# ILF3_ICONT register map
Vendor: Texas Instruments
Peripheral module from a debugger description file (folder TDA2Px).
Registers are 32-bit, access per field, reset 0x0 unless marked. A register's access mark holds for its fields unless they carry their own. Offsets are as the file gives them; lines under a group give offsets from that group; [hi:lo] are bit positions; {n}, {i} and the like mark numbered series; 'fields as' and 'values as' point back to an identical list; <NAME> marks a mode.

## ILF3_ICONT
0x00 ILF3_REVISION ro reset not defined — IP revision identifier (X.Y.R) Used by software to track features, bugs, and compatibility
  [31:0] REVISION — IP revision
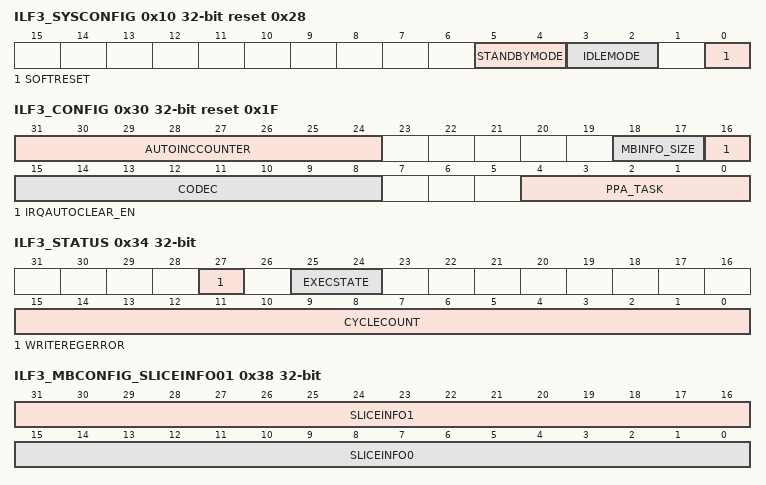
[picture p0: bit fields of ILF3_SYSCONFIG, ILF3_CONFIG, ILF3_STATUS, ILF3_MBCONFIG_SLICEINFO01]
0x10 ILF3_SYSCONFIG reset 0x28 — Clock management configuration
  [5:4] STANDBYMODE rw — Configuration of the local initiator state management mode. By definition, initiator may generate read/write transaction as long as it is out of STANDBY state.
    0=STANDBY_0 (Force-standby mode: Local initiator is unconditionally placed in STANDBY state. Backup mode, for debug only.); 1=STANDBY_1 (No-standby mode: Local initiator is unconditionally placed out of STANDBY state. Backup mode, for debug only.); 2=IP_2 (Smart-standby mode: Local initiator standby status depends on local conditions; that is, the module functional requirement from the initiator. IP module must not generate (initiator-related) wake-up events.); 3=IP_STANDBY_IP_3 (Smart-standby wakeup-capable mode: Local initiator standby status depends on local conditions; that is, the module functional requirement from the initiator. IP module may generate (master-related) wake-up events when in STANDBY state. Mode is relevant only if the appropriate IP module 'mwakeup' output is implemented.)
  [3:2] IDLEMODE rw — Configuration of the local target state management mode. By definition, target can handle read/write transaction as long as it is out of IDLE state.
    0=IDLE_IP_0 (Force-idle mode: Local target IDLE state follows (acknowledges) the system idle requests unconditionally; that is, regardless of the internal requirements of the IP module. Backup mode, for debug only.); 1=IDLE_1 (No-idle mode: Local target never enters IDLE state. Backup mode, for debug only.); 2=IDLE_IP_IP_(IRQ-_2 (Smart-idle mode: Local target IDLE state eventually follows (acknowledges) the system idle requests, depending on the internal requirements of the IP module. IP module must not generate (IRQ- or DMA-request-related) wake-up events.); 3=IDLE_IP_IP_(IRQ-_IDLE_IP_3 (Smart-idle wakeup-capable mode: Local target IDLE state eventually follows (acknowledges) the system idle requests, depending on the internal requirements of the IP module. IP module may generate (IRQ- or DMA-request-related) wake-up events when in IDLE state. Mode is relevant only if the appropriate IP module 'swakeup' output(s) is (are) implemented.)
  [0] SOFTRESET rw — Software reset (optional)
    0=Reset_done,_no_pending_action; 0=No_action; 1=Initiate_software_reset; 1=Reset_(software_or_other)_ongoing
0x18 ILF3_IRQ_EOI — End Of Interrupt number specification
  [0] LINE_NUMBER rw — Software End Of Interrupt (EOI) control. Write number of interrupt output.
    0=READ0 (EOI for interrupt output line #0); 0=EOI1 (Reads always 0 (no EOI memory)); 1=EOI1 (EOI for interrupt output line #1)
0x1C ILF3_IRQSTATUS_RAW_0 access not given — Per-event raw interrupt status vector, line 0. Raw status is set even if event is not enabled. Write 1 to set the (raw) status, mostly for debug.
  [0] EVENT0 — Settable raw status for event 0 (access RW W1toSet)
    0=No_action; 0=No_event_pending; 1=Event_pending; 1=Set_event_(debug)
0x20 ILF3_IRQSTATUS_0 access not given — Per-event 'enabled' interrupt status vector, line 0. Enabled status is not set unless event is enabled. Write 1 to clear the status after interrupt has been serviced (raw status gets cleared, that is, even if not enabled).
  [0] EVENT0 — Clearable, enabled status for event 0 (access RW W1toClr)
    0=No_action; 0=No_(enabled)_event_pending; 1=Event_pending; 1=Clear_(raw)_event
0x24 ILF3_IRQENABLE_SET_0 access not given — Per-event interrupt enable bit vector, line 0. Write 1 to set (enable interrupt). Readout equal to corresponding _CLR register.
  [0] ENABLE0 — Enable for event 0 (access RW W1toSet)
    0=No_action; 0=Interrupt_disabled_(masked); 1=Interrupt_enabled; 1=Enable_interrupt
0x28 ILF3_IRQENABLE_CLR_0 access not given — Per-event interrupt enable bit vector, line 0. Write 1 to clear (disable interrupt). Readout equal to corresponding _SET register.
  [0] ENABLE0 — Enable for event 0 (access RW W1toClr)
    0=No_action; 0=Interrupt_disabled_(masked); 1=Interrupt_enabled; 1=Disable_interrupt
0x30 ILF3_CONFIG reset 0x1F — Configuration register
  [31:24] AUTOINCCOUNTER rw — This field indicates the current increment in MB for the auto-increment mechanism. The value at reset is 0 and it is incremented at the end of each MB (or MBPair in MBAFF) process. When it reaches the MAX_COUNT value in MBCT (@0x78), it returns to 0.
  [18:17] MBINFO_SIZE rw — Selects one of the three different MBinfo sizes to be loaded.
    0=Use_Bi-16_MV_MB_info_size; 1=Use_16_MV_MB_info_size; 2=Use_Bi-4_MV_MB_info_size; 3=Forbiden_value_/_not_functional
  [16] IRQAUTOCLEAR_EN rw — 0x0: IRQ auto clear disabled, 0x1: IRQ auto clear enabled
  [15:8] CODEC rw — Indicates the codec to be used.
    0=H.264; 1=MPEG-1/-2; 2=MPEG-4; 3=VC-1; 4=AVS; 5=RV8; 6=RV9; 7=RV10; 8=On2_VP6; 9=On2_VP7; 10=H.263; 11=RCDO_(H.241); 15=GDP_filter
  [4:0] PPA_TASK rw — Bit 0: Load MB info Bit 1: Compute BS. Bit 2: Load MB. Bit 3: Filter MB. Bit 4: Store MB.
0x34 ILF3_STATUS ro — Provides information on the progress of the ILF3 execution.
  [27] WRITEREGERROR — This bit is cleared by a Start() command when in INITIALIZED or COMPLETED state.
    0=Normal_mode; 1=OCP_EXECUTING_1 (Attempting to write an internal register via an OCP write, while in EXECUTING state.)
  [25:24] EXECSTATE — Execution states.
    0=INITIALIZED; 1=HALTED; 2=EXECUTING; 3=COMPLETED
  [15:0] CYCLECOUNT — Total number of cycles executed
0x38 ILF3_MBCONFIG_SLICEINFO01 rw — MBConfig table contains pointers used by program to control the ILF3 units.
  [31:16] SLICEINFO1 — Parameter
  [15:0] SLICEINFO0 — Parameter
0x3C ILF3_MBCONFIG_SLICEINFO2 — MBConfig table contains pointers used by program to control the ILF3 units.
  [15:0] MBCONFIG_ADDRESS_SLICEINFO2 rw — Parameter
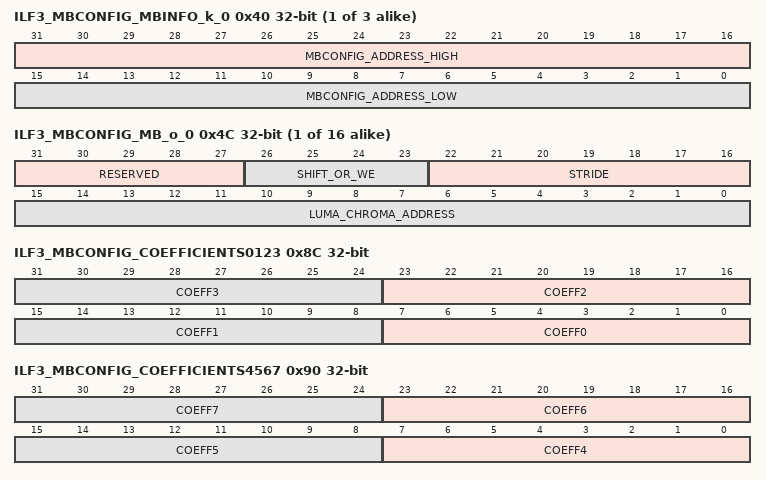
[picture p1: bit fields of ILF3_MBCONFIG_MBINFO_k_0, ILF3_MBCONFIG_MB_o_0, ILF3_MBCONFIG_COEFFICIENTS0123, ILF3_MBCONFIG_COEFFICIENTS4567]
{0x40+4i} ILF3_MBCONFIG_MBINFO_k_{i} rw (i=0..2) — MBConfig table contains pointers used by program to control the ILF3 units
  [31:16] MBCONFIG_ADDRESS_HIGH — Parameter
  [15:0] MBCONFIG_ADDRESS_LOW — Parameter
{0x4C+4i} ILF3_MBCONFIG_MB_o_{i} (i=0..15) — MBConfig table contains pointers used by program to control the ILF3 units
  [31:27] RESERVED ro — Read returns 0
  [26:23] SHIFT_OR_WE rw — Parameter, see and .
  [22:16] STRIDE rw — This field allows to increment the base address with the stride value at each iteration.
  [15:0] LUMA_CHROMA_ADDRESS rw — SL2 address pointer
0x8C ILF3_MBCONFIG_COEFFICIENTS0123 rw — MBConfig table contains pointers used by program to control the ILF3 units.
  [8n+7:8n] COEFF{n} (n=0..3) — GDP coefficient {n}
0x90 ILF3_MBCONFIG_COEFFICIENTS4567 rw — MBConfig table contains pointers used by program to control the ILF3 units.
  [8n-25:8n-32] COEFF{n} (n=4..7) — GDP coefficient {n}
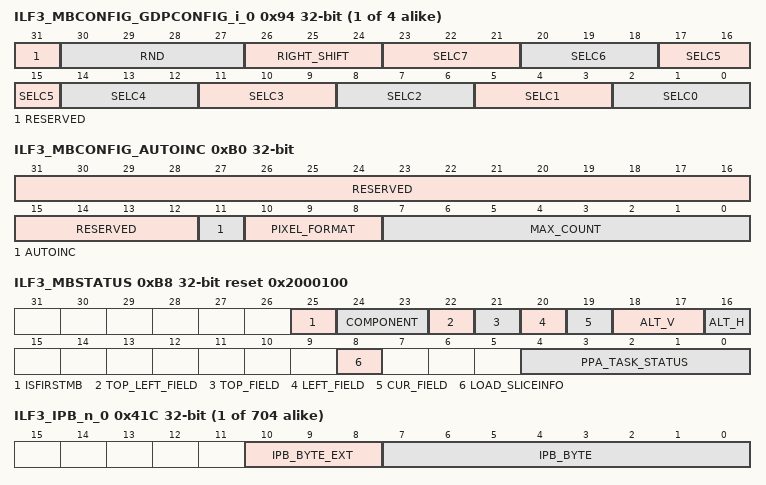
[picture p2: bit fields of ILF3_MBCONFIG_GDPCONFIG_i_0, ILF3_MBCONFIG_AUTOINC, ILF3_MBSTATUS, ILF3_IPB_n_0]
{0x94+4i} ILF3_MBCONFIG_GDPCONFIG_i_{i} (i=0..3) — MBConfig table contains pointers used by program to control the ILF3 units
  [31] RESERVED ro — Read returns 0.
  [30:27] RND rw — Rounding selection
  [26:24] RIGHT_SHIFT rw — Shift right value
  [3n+2:3n] SELC{n} rw (n=0..7) — Coefficient selection for GDP, P{n} multiplication
0xB0 ILF3_MBCONFIG_AUTOINC — MBConfig table contains pointers used by program to control the ILF3 units.
  [31:12] RESERVED ro — Read returns 0.
  [11] AUTOINC rw — This bit must set to 1 to activate the auto-increment scheme.
  [10:8] PIXEL_FORMAT rw — This field indicates the number of pixel rows in the top-row buffer and also the number of rows of 8-bit pixels and 16-bit pixels (VC-1 case with OVT activated).
  [7:0] MAX_COUNT rw — Maximum value of Counter for auto-increment. Usually corresponds to the number of MB in one row.
0xB4 ILF3_MBCONFIG_NEXTMBCONFIG — MBConfig table contains pointers used by program to control the ILF3 units.
  [15:0] NEXTMBCONFIGADDRESS rw — Contains the next MB address
0xB8 ILF3_MBSTATUS reset 0x2000100 (reset mask 0xFFF9FFE0) — Provides MB properties
  [25] ISFIRSTMB rw — Indicates which MB of the MB pair is being processed.
    0=MB_MB_MB_0 (The current MB is the second MB of the MB pair.); 1=MB_MB_MB_1 (The current MB is the first MB of the MB pair.)
  [24:23] COMPONENT rw — Indicates if IPB contains Luma or Chroma pixels. Ex: in H.264 0: Luma pixels 1: Chroma pixels
  [22] TOP_LEFT_FIELD rw — Indicates the type of the top-left MB pair.
    0=Top-left_MB_pair_is_frame; 1=Top-left_MB_pair_is_field
  [21] TOP_FIELD rw — Indicates the type of the top MB pair.
    0=Top_MB_pair_is_frame; 1=Top_MB_pair_is_field
  [20] LEFT_FIELD rw — Indicates the type of the left MB pair.
    0=Lleft_MB_pair_is_frame; 1=Left_MB_pair_is_field
  [19] CUR_FIELD rw — Indicates the type of the current MB.
    0=Current_MB_pair_is_frame; 1=Current_MB_pair_is_field
  [18:17] ALT_V rw — Indicates the type of left edge.
    0=Left_edge_is_not_alternate; 1=Left_edge_is_frame/field; 2=Left_edge_is_field/frame; 3=Forbiden/not_functional
  [16] ALT_H rw — Indicates the type of the top horizontal edge.
    0=Top_horizontal_edge_is_not_frame/field; 1=Top_horizontal_edge_is_frame/field
  [8] LOAD_SLICEINFO rw — This flag indicates if the slice information must be updated or not.
    0=LOAD_SLICEINFO_0_r (Slice_info is up to date, no load required.); 1=LOAD_SLICEINFO_1_r (Slice_info is out of date, load is required.)
  [4:0] PPA_TASK_STATUS ro — 1 means which elementary task has been executed. Bit 0: Load MB info Bit 1: Compute BS Bit 2: Load MB Bit 3: Filter MB Bit 4: Store MB
{0xBC+4i} ILF3_SLICESTATUS_k_{i} rw (i=0..2) — MBConfig table contains pointers used by program to control the ILF3 units
  [31:0] SLICEINFO — Slice information register.See, Load SLICEINFO. .
{0xE0+4i} ILF3_QP_m_{i} (reset mask 0xFFFFFFC0) (i=0..17) — Quantization parameter
  [5:0] QP rw
{0x128+4i} ILF3_QP_IDX_j_{i} (reset mask 0xFFFFFFF8) (i=0..39) — Quantization parameter index
  [2:0] QP_IDX rw — QP index
{0x1C8+4i} ILF3_BS_l_{i} (reset mask 0xFFFFFFF0) (i=0..148) — Boundary strength
  [3:0] BS rw — Boundary strength for H.264, but those fields are also used for filter flag for other codecs, such as V1 and OVT, Luma, and Chroma, when they are different. This lead currently leads in the worst case up to 149 BS values.
{0x41C+4i} ILF3_IPB_n_{i} (reset mask 0xFFFFF800) (i=0..703) — Input buffer bank
  [10:8] IPB_BYTE_EXT rw — 3-bit extension used in V1 OVT process
  [7:0] IPB_BYTE rw — Byte element of IPB
0xFFC ILF3_COMMAND (reset mask 0xFFFFFFF8) — ILF3 command register: A write to this register decodes a command. DATA/COMMAND 0x1 -> Start() 0x2 -> Stop() 0x3 -> DbgEn() 0x4 -> DbgDis() 0x5 -> DbgStep().
  [2:0] CMD wo — DATA/COMMAND 0x1 -&gt; Start() 0x2 -&gt; Stop() 0x3 -&gt; DbgEn() 0x4 -&gt; DbgDis() 0x5 -&gt; DbgStep()
